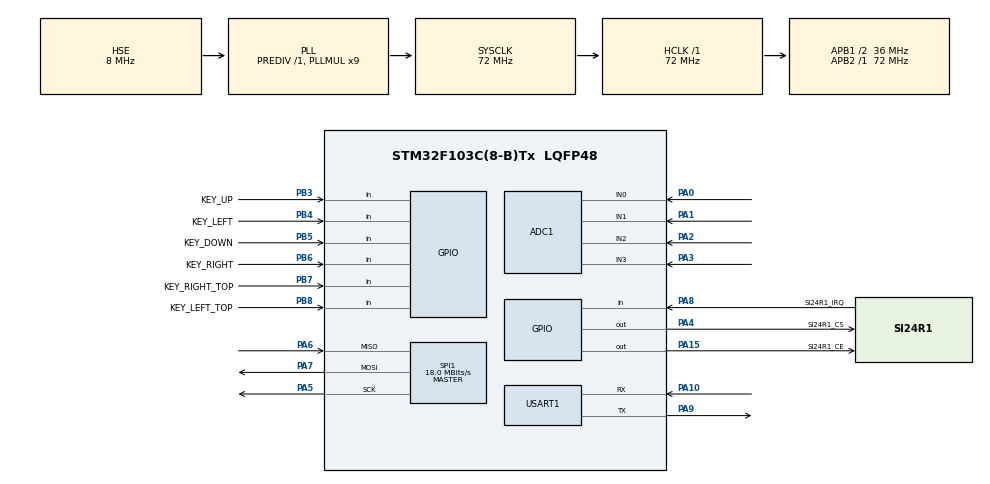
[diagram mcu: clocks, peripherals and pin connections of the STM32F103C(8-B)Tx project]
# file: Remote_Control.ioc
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ADC1.Channel-1\#ChannelRegularConversion=ADC_CHANNEL_0
ADC1.Channel-2\#ChannelRegularConversion=ADC_CHANNEL_1
ADC1.Channel-3\#ChannelRegularConversion=ADC_CHANNEL_2
ADC1.Channel-4\#ChannelRegularConversion=ADC_CHANNEL_3
ADC1.ContinuousConvMode=ENABLE
ADC1.EnableAnalogWatchDog=false
ADC1.EnableInjectedConversion=DISABLE
ADC1.EnableRegularConversion=ENABLE
ADC1.InjNumberOfConversion=0
ADC1.NbrOfConversion=4
ADC1.NbrOfConversionFlag=1
ADC1.Rank-1\#ChannelRegularConversion=1
ADC1.Rank-2\#ChannelRegularConversion=2
ADC1.Rank-3\#ChannelRegularConversion=3
ADC1.Rank-4\#ChannelRegularConversion=4
ADC1.SamplingTime-1\#ChannelRegularConversion=ADC_SAMPLETIME_13CYCLES_5
ADC1.SamplingTime-2\#ChannelRegularConversion=ADC_SAMPLETIME_13CYCLES_5
ADC1.SamplingTime-3\#ChannelRegularConversion=ADC_SAMPLETIME_13CYCLES_5
ADC1.SamplingTime-4\#ChannelRegularConversion=ADC_SAMPLETIME_13CYCLES_5
ADC1.master=1
Dma.ADC1.0.Direction=DMA_PERIPH_TO_MEMORY
Dma.ADC1.0.Instance=DMA1_Channel1
Dma.ADC1.0.MemDataAlignment=DMA_MDATAALIGN_HALFWORD
Dma.ADC1.0.MemInc=DMA_MINC_ENABLE
Dma.ADC1.0.Mode=DMA_CIRCULAR
Dma.ADC1.0.PeriphDataAlignment=DMA_PDATAALIGN_HALFWORD
Dma.ADC1.0.PeriphInc=DMA_PINC_DISABLE
Dma.ADC1.0.Priority=DMA_PRIORITY_LOW
Dma.Request0=ADC1
Mcu.Family=STM32F1
Mcu.Name=STM32F103C(8-B)Tx
Mcu.Package=LQFP48
NVIC.PriorityGroup=NVIC_PRIORITYGROUP_4
PA0-WKUP.Signal=ADCx_IN0
PA1.Signal=ADCx_IN1
PA10.Mode=Asynchronous
PA10.Signal=USART1_RX
PA13.Mode=Serial_Wire
PA13.Signal=SYS_JTMS-SWDIO
PA14.Mode=Serial_Wire
PA14.Signal=SYS_JTCK-SWCLK
PA15.GPIO_Label=Si24R1_CE
PA15.PinState=GPIO_PIN_SET
PA15.Signal=GPIO_Output
PA2.Signal=ADCx_IN2
PA3.Signal=ADCx_IN3
PA4.GPIO_Label=Si24R1_CS
PA4.PinState=GPIO_PIN_SET
PA4.Signal=GPIO_Output
PA5.Mode=Full_Duplex_Master
PA5.Signal=SPI1_SCK
PA6.Mode=Full_Duplex_Master
PA6.Signal=SPI1_MISO
PA7.Mode=Full_Duplex_Master
PA7.Signal=SPI1_MOSI
PA8.GPIO_Label=Si24R1_IRQ
PA8.GPIO_PuPd=GPIO_PULLUP
PA8.Signal=GPIO_Input
PA9.Mode=Asynchronous
PA9.Signal=USART1_TX
PB3.GPIO_Label=KEY_UP
PB3.GPIO_PuPd=GPIO_PULLUP
PB3.Signal=GPIO_Input
PB4.GPIO_Label=KEY_LEFT
PB4.GPIO_PuPd=GPIO_PULLUP
PB4.Signal=GPIO_Input
PB5.GPIO_Label=KEY_DOWN
PB5.GPIO_PuPd=GPIO_PULLUP
PB5.Signal=GPIO_Input
PB6.GPIO_Label=KEY_RIGHT
PB6.GPIO_PuPd=GPIO_PULLUP
PB6.Signal=GPIO_Input
PB7.GPIO_Label=KEY_RIGHT_TOP
PB7.GPIO_PuPd=GPIO_PULLUP
PB7.Signal=GPIO_Input
PB8.GPIO_Label=KEY_LEFT_TOP
PB8.GPIO_PuPd=GPIO_PULLUP
PB8.Signal=GPIO_Input
PC14-OSC32_IN.Mode=LSE-External-Oscillator
PC14-OSC32_IN.Signal=RCC_OSC32_IN
PC15-OSC32_OUT.Mode=LSE-External-Oscillator
PC15-OSC32_OUT.Signal=RCC_OSC32_OUT
PD0-OSC_IN.Mode=HSE-External-Oscillator
PD0-OSC_IN.Signal=RCC_OSC_IN
PD1-OSC_OUT.Mode=HSE-External-Oscillator
PD1-OSC_OUT.Signal=RCC_OSC_OUT
ProjectManager.HeapSize=0x200
ProjectManager.StackSize=0x800
ProjectManager.TargetToolchain=MDK-ARM V5.32
RCC.ADCPresc=RCC_ADCPCLK2_DIV6
RCC.AHBFreq_Value=72000000
RCC.APB1CLKDivider=RCC_HCLK_DIV2
RCC.APB1Freq_Value=36000000
RCC.APB1TimFreq_Value=72000000
RCC.APB2Freq_Value=72000000
RCC.APB2TimFreq_Value=72000000
RCC.HCLKFreq_Value=72000000
RCC.PLLMUL=RCC_PLL_MUL9
RCC.PLLSourceVirtual=RCC_PLLSOURCE_HSE
RCC.SYSCLKFreq_VALUE=72000000
RCC.SYSCLKSource=RCC_SYSCLKSOURCE_PLLCLK
RCC.USBFreq_Value=72000000
SH.ADCx_IN0.0=ADC1_IN0,IN0
SH.ADCx_IN1.0=ADC1_IN1,IN1
SH.ADCx_IN2.0=ADC1_IN2,IN2
SH.ADCx_IN3.0=ADC1_IN3,IN3
SPI1.BaudRatePrescaler=SPI_BAUDRATEPRESCALER_4
SPI1.CalculateBaudRate=18.0 MBits/s
SPI1.Direction=SPI_DIRECTION_2LINES
SPI1.Mode=SPI_MODE_MASTER
SPI1.VirtualType=VM_MASTER
USART1.VirtualMode=VM_ASYNC
board=custom

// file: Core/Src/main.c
/* USER CODE BEGIN Header */
/**
  ******************************************************************************
  * @file           : main.c
  * @brief          : Main program body
  ******************************************************************************
  * @attention
  *
  * Copyright (c) 2025 STMicroelectronics.
  * All rights reserved.
  *
  * This software is licensed under terms that can be found in the LICENSE file
  * in the root directory of this software component.
  * If no LICENSE file comes with this software, it is provided AS-IS.
  *
  ******************************************************************************
  */
/* USER CODE END Header */
#include "main.h"
#include "adc.h"
#include "dma.h"
#include "spi.h"
#include "usart.h"
#include "gpio.h"

/* USER CODE BEGIN Includes */
#include "App_Task.h"
/* USER CODE END Includes */

void SystemClock_Config(void);

int main(void)
{

  /* MCU Configuration--------------------------------------------------------*/

  /* Reset of all peripherals, Initializes the Flash interface and the Systick. */
  HAL_Init();

  /* Configure the system clock */
  SystemClock_Config();

  /* Initialize all configured peripherals */
  MX_GPIO_Init();
  MX_DMA_Init();
  MX_SPI1_Init();
  MX_USART1_UART_Init();
  MX_ADC1_Init();

  /* Infinite loop */
  /* USER CODE BEGIN WHILE */
  /*启动实时系统*/
	App_Task_FreeRTOSStart();
  while (1)
  {
    /* USER CODE END WHILE */

  }
}

void SystemClock_Config(void)
{
  RCC_OscInitTypeDef RCC_OscInitStruct = {0};
  RCC_ClkInitTypeDef RCC_ClkInitStruct = {0};
  RCC_PeriphCLKInitTypeDef PeriphClkInit = {0};

  /** Initializes the RCC Oscillators according to the specified parameters
  * in the RCC_OscInitTypeDef structure.
  */
  RCC_OscInitStruct.OscillatorType = RCC_OSCILLATORTYPE_HSE;
  RCC_OscInitStruct.HSEState = RCC_HSE_ON;
  RCC_OscInitStruct.HSEPredivValue = RCC_HSE_PREDIV_DIV1;
  RCC_OscInitStruct.HSIState = RCC_HSI_ON;
  RCC_OscInitStruct.PLL.PLLState = RCC_PLL_ON;
  RCC_OscInitStruct.PLL.PLLSource = RCC_PLLSOURCE_HSE;
  RCC_OscInitStruct.PLL.PLLMUL = RCC_PLL_MUL9;
  if (HAL_RCC_OscConfig(&RCC_OscInitStruct) != HAL_OK)
  {
    Error_Handler();
  }

  /** Initializes the CPU, AHB and APB buses clocks
  */
  RCC_ClkInitStruct.ClockType = RCC_CLOCKTYPE_HCLK|RCC_CLOCKTYPE_SYSCLK
                              |RCC_CLOCKTYPE_PCLK1|RCC_CLOCKTYPE_PCLK2;
  RCC_ClkInitStruct.SYSCLKSource = RCC_SYSCLKSOURCE_PLLCLK;
  RCC_ClkInitStruct.AHBCLKDivider = RCC_SYSCLK_DIV1;
  RCC_ClkInitStruct.APB1CLKDivider = RCC_HCLK_DIV2;
  RCC_ClkInitStruct.APB2CLKDivider = RCC_HCLK_DIV1;

  if (HAL_RCC_ClockConfig(&RCC_ClkInitStruct, FLASH_LATENCY_2) != HAL_OK)
  {
    Error_Handler();
  }
  PeriphClkInit.PeriphClockSelection = RCC_PERIPHCLK_ADC;
  PeriphClkInit.AdcClockSelection = RCC_ADCPCLK2_DIV6;
  if (HAL_RCCEx_PeriphCLKConfig(&PeriphClkInit) != HAL_OK)
  {
    Error_Handler();
  }
}

void Error_Handler(void)
{
  __disable_irq();
  while (1)
  {
  }
}
